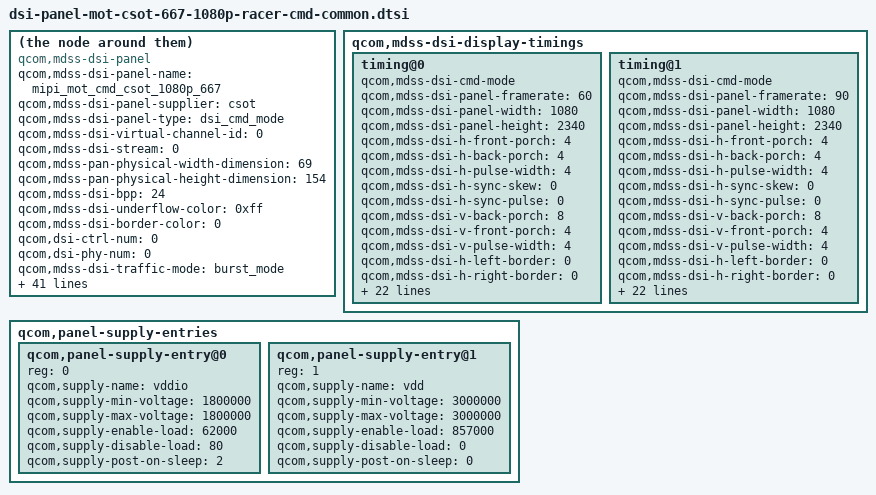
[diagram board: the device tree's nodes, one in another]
/* Copyright (c) 2019, The Linux Foundation. All rights reserved.
 *
 * This program is free software; you can redistribute it and/or modify
 * it under the terms of the GNU General Public License version 2 and
 * only version 2 as published by the Free Software Foundation.
 *
 * This program is distributed in the hope that it will be useful,
 * but WITHOUT ANY WARRANTY; without even the implied warranty of
 * MERCHANTABILITY or FITNESS FOR A PARTICULAR PURPOSE.  See the
 * GNU General Public License for more details.
 */

compatible = "qcom,mdss-dsi-panel";
qcom,mdss-dsi-panel-name = "mipi_mot_cmd_csot_1080p_667";
qcom,mdss-dsi-panel-supplier = "csot";
qcom,mdss-dsi-panel-type = "dsi_cmd_mode";
qcom,mdss-dsi-virtual-channel-id = <0>;
qcom,mdss-dsi-stream = <0>;
/* Need to fix with and height */
qcom,mdss-pan-physical-width-dimension = <69>;
qcom,mdss-pan-physical-height-dimension = <154>;
qcom,mdss-dsi-bpp = <24>;
qcom,mdss-dsi-underflow-color = <0xff>;
qcom,mdss-dsi-border-color = <0>;

qcom,dsi-ctrl-num = <0>;
qcom,dsi-phy-num = <0>;

qcom,mdss-dsi-traffic-mode = "burst_mode";
qcom,mdss-dsi-bllp-eof-power-mode;
qcom,mdss-dsi-bllp-power-mode;
qcom,mdss-dsi-lane-0-state;
qcom,mdss-dsi-lane-1-state;
qcom,mdss-dsi-lane-2-state;
qcom,mdss-dsi-lane-3-state;

qcom,mdss-dsi-dma-trigger = "trigger_sw";
qcom,mdss-dsi-mdp-trigger = "none";
qcom,mdss-dsi-reset-sequence = <0 11>, <1 1>, <0 1>, <1 11>;
qcom,mdss-dsi-lp11-init;
qcom,mdss-dsi-tx-eot-append;
qcom,mdss-dsi-te-pin-select = <1>;
qcom,mdss-dsi-te-dcs-command = <1>;

qcom,mdss-dsi-te-using-te-pin;

qcom,esd-check-enabled;
qcom,mdss-dsi-panel-status-check-mode = "reg_read";
qcom,mdss-dsi-panel-status-command = [06 01 00 01 00 00 01 0a];
qcom,mdss-dsi-panel-status-command-state = "dsi_lp_mode";
qcom,mdss-dsi-panel-status-value = <0x9c>;
qcom,mdss-dsi-panel-status-read-length = <1>;

qcom,bklt-dcs-2bytes-enabled;
qcom,mdss-dsi-bl-min-level = <3>;
qcom,mdss-dsi-bl-max-level = <2047>;
qcom,mdss-dsi-bl-pmic-control-type = "bl_ctrl_dcs";

qcom,mdss-dsi-hbm-on-command = [
		39 01 00 00 00 00 03 51 0F FF];
qcom,mdss-dsi-hbm-off-command = [
		39 01 00 00 00 00 03 51 07 FF];

qcom,mdss-dsi-acl-on-command = [
		39 01 00 00 00 00 06 F0 55 AA 52 08 00
		15 01 00 00 00 00 02 B0 0C
		15 01 00 00 00 00 02 55 05];
qcom,mdss-dsi-acl-off-command = [
		15 01 00 00 00 00 02 55 00];

qcom,mdss-dsi-panel-hbm-is-51cmd;

qcom,dynamic-mode-switch-enabled;
qcom,dynamic-mode-switch-type = "dynamic-resolution-switch-immediate";

qcom,mdss-dsi-display-timings {
	timing@0{
		/* 60 FPS */
		qcom,mdss-dsi-cmd-mode;
		qcom,mdss-dsi-panel-framerate = <60>;
		qcom,mdss-dsi-panel-width = <1080>;
		qcom,mdss-dsi-panel-height = <2340>;
		qcom,mdss-dsi-h-front-porch = <4>;
		qcom,mdss-dsi-h-back-porch = <4>;
		qcom,mdss-dsi-h-pulse-width = <4>;
		qcom,mdss-dsi-h-sync-skew = <0>;
		qcom,mdss-dsi-h-sync-pulse = <0>;
		qcom,mdss-dsi-v-back-porch = <8>;
		qcom,mdss-dsi-v-front-porch = <4>;
		qcom,mdss-dsi-v-pulse-width = <4>;
		qcom,mdss-dsi-h-left-border = <0>;
		qcom,mdss-dsi-h-right-border = <0>;
		qcom,mdss-dsi-v-top-border = <0>;
		qcom,mdss-dsi-v-bottom-border = <0>;
		qcom,mdss-dsi-panel-jitter = <0x20 0xa>; /* 60fps +/- 2 */
		qcom,mdss-dsi-timing-switch-command = [
			39 01 00 00 00 00 06 F0 55 AA 52 08 00 /* Page 0 */
			15 01 00 00 00 00 02 6F 0E
			15 01 00 00 00 00 02 BA 18
			15 01 00 00 00 00 02 6F 03
			39 01 00 00 00 00 04 C0 80 00 00
			15 01 00 00 00 00 02 26 01];
		qcom,mdss-dsi-on-command = [
			39 00 00 00 00 00 06 F0 55 AA 52 08 00
			39 00 00 00 00 00 08 B7 AA AA AA AA AA 00 00
			15 00 00 00 00 00 02 6F 06
			39 00 00 00 00 00 0B B5 4B 19 51 00 00 4B 23 51 00 00

			39 00 00 00 00 00 05 FF AA 55 A5 81
			15 00 00 00 00 00 02 6F 0D
			15 00 00 00 00 00 02 F3 AB
			/* Set OSC 101.6Mhz */
			15 00 00 00 00 00 02 6F 05
			39 00 00 00 00 00 03 FD 00 DA
			/* End Set OSC */
			39 00 00 00 00 00 05 FF AA 55 A5 00
			39 00 00 00 00 00 06 F0 55 AA 52 08 01 /* Page */
			/*TSP_VTE, TSP_HTE*/
			39 00 00 00 00 00 04 D1 07 02 2C
			39 00 00 00 00 00 06 F0 55 AA 52 08 00 /* Page 0 */
			/*GPO0=TE, GPO1=ALL MIPI error, GPO2=TSP_HTE, GPO3=TSP_CTE*/
			39 00 00 00 00 00 06 BE 0E 00 94 13 1F
			/* Framne rate = 60hz */
			15 00 00 00 00 00 02 B2 00 /* backlight fix */
			15 00 00 00 00 00 02 6F 0E
			15 00 00 00 00 00 02 BA 18
			15 00 00 00 00 00 02 6F 03
			39 00 00 00 00 00 04 C0 80 00 00
			15 00 00 00 00 00 02 26 01
			/* Done with frame rate setting */
			05 00 00 00 00 00 01 35  /* Set tear on */
			15 00 00 00 00 00 02 53 20 /* HBM off ,dimming=1frame*/
			/* Spec calls for 51 06 40 0F FF*/
			39 00 00 00 00 00 05 51 00 00 0F FF
			39 00 00 00 00 00 05 2A 00 00 04 37 /* Column Addr set */
			39 00 00 00 00 00 05 2B 00 00 09 23 /* Row Addr set */
			39 00 00 00 00 00 13 93 89 28 00 14 02 00 02 0E 01 E8 00 07 05 0E 05 16 10 F0
			15 00 00 00 00 00 02 90 01  /* Compression method selection*/
			15 00 00 00 00 00 02 03 11 /* Compression mode */
			05 01 00 00 00 00 01 2C /* Memory write */
			05 01 00 00 64 00 01 11
			15 00 00 00 00 00 02 55 00 /* ACL OFF */
			05 01 00 00 00 00 01 29];  /* display on */
		qcom,mdss-dsi-off-command = [
			05 01 00 00 00 00 01 28     /* display_off */
			05 01 00 00 78 00 01 10];   /* enter sleep mode */

			qcom,mdss-dsi-timing-switch-command-state = "dsi_lp_mode";
			qcom,mdss-dsi-on-command-state = "dsi_lp_mode";
			qcom,mdss-dsi-off-command-state = "dsi_lp_mode";
			qcom,mdss-dsi-force-tx-mode = "dsi_hs_mode";

			qcom,compression-mode = "dsc";
			/* Why QCOM doesn't use this, even it used 2 encoder
			 * as for that dsi_sw43404_amoled_cmd, for ex */
			/* qcom,mdss-dsc-encoders = <2>; */
			qcom,mdss-dsc-version = <0x11>;
			qcom,mdss-dsc-slice-height = <20>;
			qcom,mdss-dsc-slice-width = <540>;
			qcom,mdss-dsc-slice-per-pkt = <2>;
			qcom,mdss-dsc-bit-per-component = <8>;
			qcom,mdss-dsc-bit-per-pixel = <8>;
			qcom,mdss-dsc-block-prediction-enable;
	};

	timing@1{
		/* 90 FPS */
		qcom,mdss-dsi-cmd-mode;
		qcom,mdss-dsi-panel-framerate = <90>;
		qcom,mdss-dsi-panel-width = <1080>;
		qcom,mdss-dsi-panel-height = <2340>;
		qcom,mdss-dsi-h-front-porch = <4>;
		qcom,mdss-dsi-h-back-porch = <4>;
		qcom,mdss-dsi-h-pulse-width = <4>;
		qcom,mdss-dsi-h-sync-skew = <0>;
		qcom,mdss-dsi-h-sync-pulse = <0>;
		qcom,mdss-dsi-v-back-porch = <8>;
		qcom,mdss-dsi-v-front-porch = <4>;
		qcom,mdss-dsi-v-pulse-width = <4>;
		qcom,mdss-dsi-h-left-border = <0>;
		qcom,mdss-dsi-h-right-border = <0>;
		qcom,mdss-dsi-v-top-border = <0>;
		qcom,mdss-dsi-v-bottom-border = <0>;
		qcom,mdss-dsi-panel-jitter = <0x15 0xa>; /* 90fps +/- 2 */
		qcom,mdss-dsi-timing-switch-command = [
			39 01 00 00 00 00 06 F0 55 AA 52 08 00 /* Page 0 */
			15 01 00 00 00 00 02 6F 0E
			15 01 00 00 00 00 02 BA 18
			15 01 00 00 00 00 02 6F 03
			39 01 00 00 00 00 04 C0 00 00 00
			15 01 00 00 00 00 02 26 02];
		qcom,mdss-dsi-on-command = [
			39 00 00 00 00 00 06 F0 55 AA 52 08 00
			39 00 00 00 00 00 08 B7 AA AA AA AA AA 00 00
			15 00 00 00 00 00 02 6F 06
			39 00 00 00 00 00 0B B5 4B 19 51 00 00 4B 23 51 00 00

			39 00 00 00 00 00 05 FF AA 55 A5 81
			15 00 00 00 00 00 02 6F 0D
			15 00 00 00 00 00 02 F3 AB
			/* Set OSC 101.6Mhz */
			15 00 00 00 00 00 02 6F 05
			39 00 00 00 00 00 03 FD 00 DA
			/* End Set OSC */
			39 00 00 00 00 00 05 FF AA 55 A5 00
			39 00 00 00 00 00 06 F0 55 AA 52 08 01 /* Page 1*/
			/*TSP_VTE, TSP_HTE*/
			39 00 00 00 00 00 04 D1 07 02 2C
			39 00 00 00 00 00 06 F0 55 AA 52 08 00 /* Page 0*/
			/*GPO0=TE, GPO1=ALL MIPI error, GPO2=TSP_HTE, GPO3=TSP_CTE*/
			39 00 00 00 00 00 06 BE 0E 00 94 13 1F
			/* Framne rate = 90hz */
			15 00 00 00 00 00 02 B2 00 /* backlight fix */
			15 00 00 00 00 00 02 6F 0E
			15 00 00 00 00 00 02 BA 18
			15 00 00 00 00 00 02 6F 03
			39 00 00 00 00 00 04 C0 00 00 00
			15 00 00 00 00 00 02 26 02
			/* Done with frame rate setting */
			05 00 00 00 00 00 01 35	 /* Set tear on */
			15 00 00 00 00 00 02 53 20 /* HBM off ,dimming=1frame*/
			/* Spec calls for 51 06 40 0F FF*/
			39 00 00 00 00 00 05 51 00 00 0F FF
			39 00 00 00 00 00 05 2A 00 00 04 37 /* Column Addr set */
			39 00 00 00 00 00 05 2B 00 00 09 23 /* Row Addr set */
			39 00 00 00 00 00 13 93 89 28 00 14 02 00 02 0E 01 E8 00 07 05 0E 05 16 10 F0
			15 00 00 00 00 00 02 90 01  /* Compression method selection*/
			15 00 00 00 00 00 02 03 11 /* Compression mode */
			05 01 00 00 00 00 01 2C /* Memory write */
			05 01 00 00 64 00 01 11
			15 00 00 00 00 00 02 55 00      /* ACL OFF */
			05 01 00 00 00 00 01 29];	/* display on */
		qcom,mdss-dsi-off-command = [
			05 01 00 00 00 00 01 28		/* display_off */
			05 01 00 00 78 00 01 10];	/* enter sleep mode */

		qcom,mdss-dsi-timing-switch-command-state = "dsi_lp_mode";
		qcom,mdss-dsi-on-command-state = "dsi_lp_mode";
		qcom,mdss-dsi-off-command-state = "dsi_lp_mode";
		qcom,mdss-dsi-force-tx-mode = "dsi_hs_mode";

		qcom,compression-mode = "dsc";
		/* Why QCOM doesn't use this, even it used 2 encoder
		 * as for that dsi_sw43404_amoled_cmd, for ex */
		/* qcom,mdss-dsc-encoders = <2>; */
		qcom,mdss-dsc-version = <0x11>;
		qcom,mdss-dsc-slice-height = <20>;
		qcom,mdss-dsc-slice-width = <540>;
		qcom,mdss-dsc-slice-per-pkt = <2>;
		qcom,mdss-dsc-bit-per-component = <8>;
		qcom,mdss-dsc-bit-per-pixel = <8>;
		qcom,mdss-dsc-block-prediction-enable;
	};

};
qcom,panel-supply-entries {
	#address-cells = <1>;
	#size-cells = <0>;

	qcom,panel-supply-entry@0 {
		reg = <0>;
		qcom,supply-name = "vddio";
		qcom,supply-min-voltage = <1800000>;
		qcom,supply-max-voltage = <1800000>;
		qcom,supply-enable-load = <62000>;
		qcom,supply-disable-load = <80>;
		qcom,supply-post-on-sleep = <2>;
	};

	qcom,panel-supply-entry@1 {
		reg = <1>;
	        qcom,supply-name = "vdd";
		qcom,supply-min-voltage = <3000000>;
		qcom,supply-max-voltage = <3000000>;
		qcom,supply-enable-load = <857000>;
		qcom,supply-disable-load = <0>;
		qcom,supply-post-on-sleep = <0>;
	};
};
